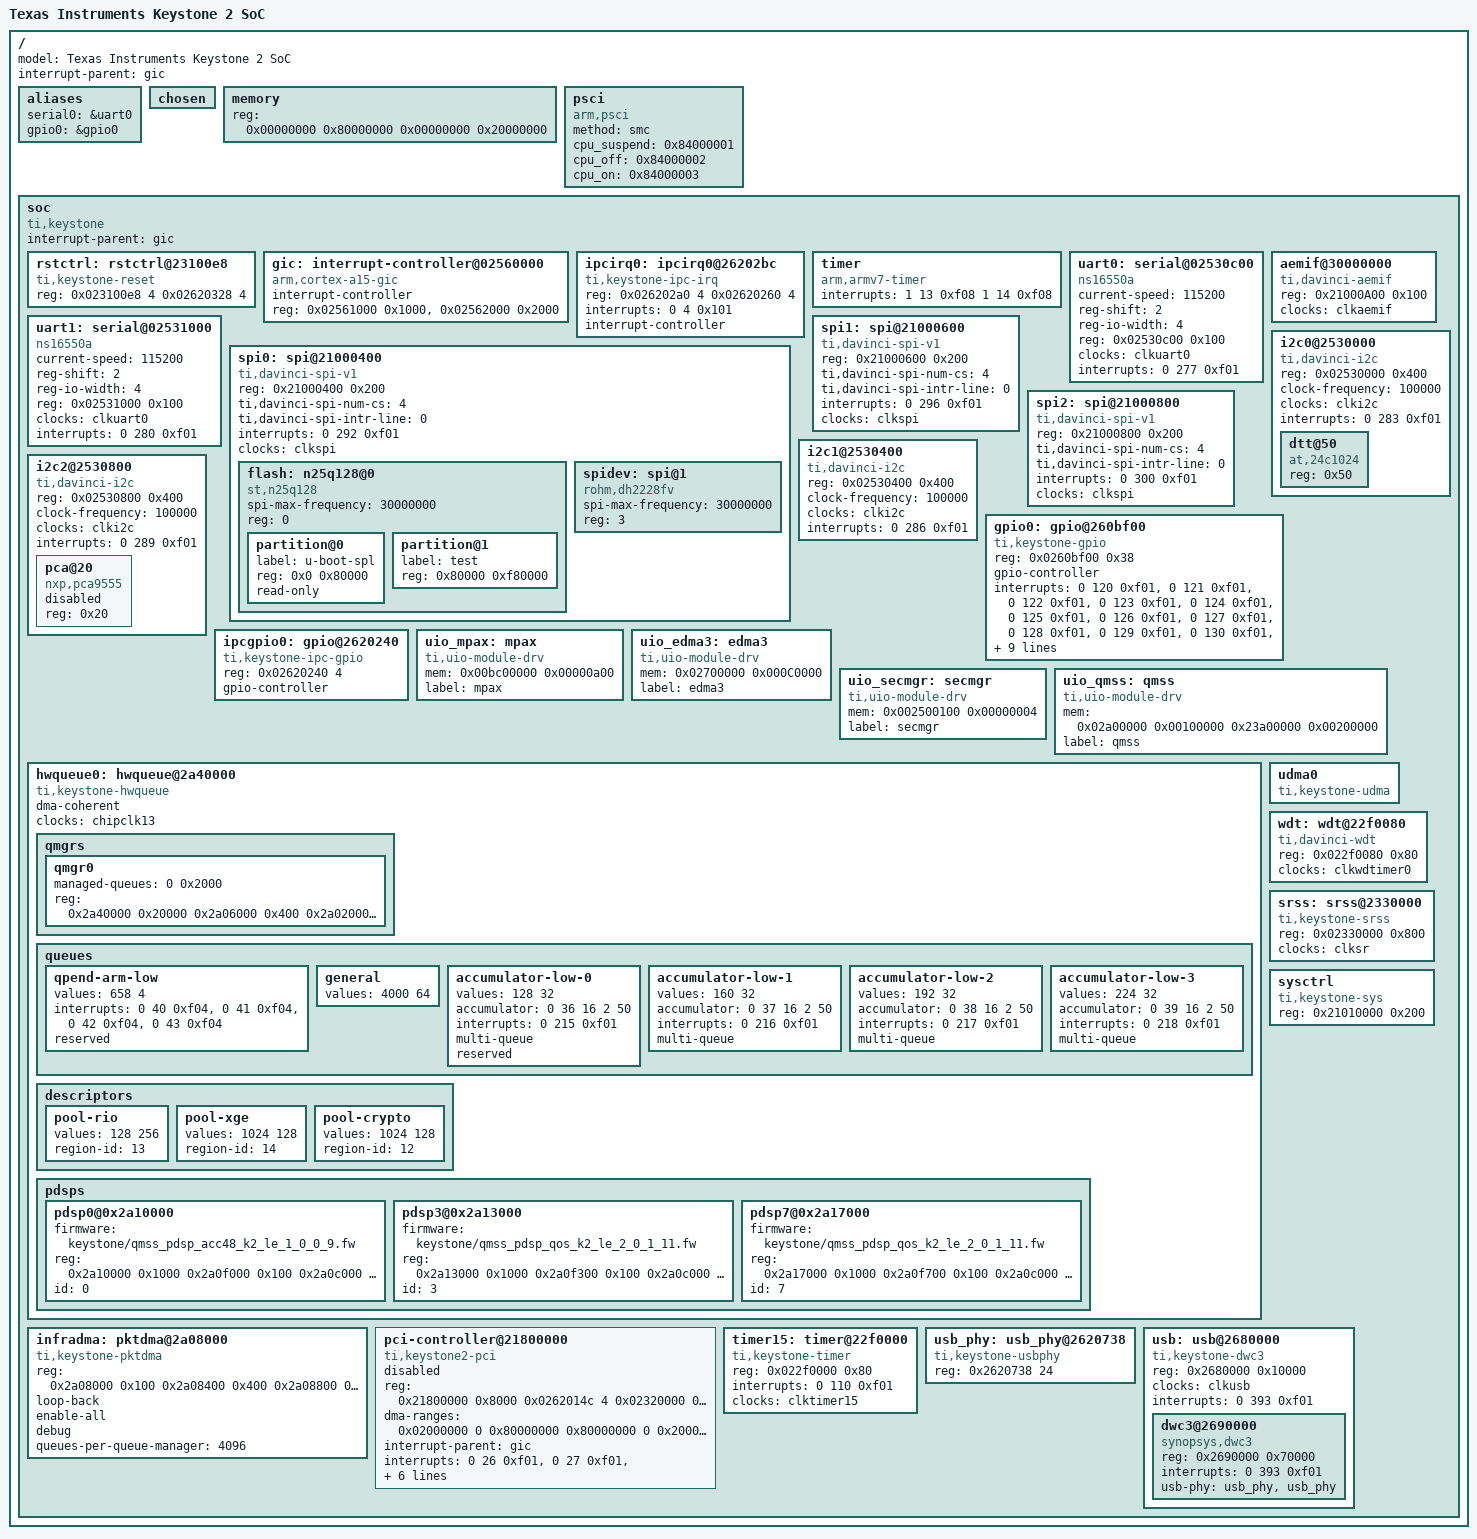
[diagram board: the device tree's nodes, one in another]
/*
 * Copyright 2014 Texas Instruments, Inc.
 *
 * Common DT bindings for Keystone SoCs
 *
 * This program is free software; you can redistribute it and/or modify
 * it under the terms of the GNU General Public License version 2 as
 * published by the Free Software Foundation.
 */

/include/ "skeleton.dtsi"

/ {
	model = "Texas Instruments Keystone 2 SoC";
	#address-cells = <2>;
	#size-cells = <2>;
	interrupt-parent = <&gic>;

	aliases {
		serial0	= &uart0;
		gpio0   = &gpio0;
	};

	chosen {
	};

	memory {
		reg = <0x00000000 0x80000000 0x00000000 0x20000000>;
	};

	psci {
		compatible	= "arm,psci";
		method		= "smc";
		cpu_suspend	= <0x84000001>;
		cpu_off		= <0x84000002>;
		cpu_on		= <0x84000003>;
	};

	soc {
		#address-cells = <1>;
		#size-cells = <1>;
		compatible = "ti,keystone","simple-bus";
		interrupt-parent = <&gic>;
		ranges = <0x0 0x0 0x0 0xc0000000>;

		rstctrl:rstctrl@23100e8 {
			compatible = "ti,keystone-reset";
			reg = <0x023100e8 4	/* pll reset control reg */
				0x02620328 4>;	/* rstmux8 register */
		};

		/include/ "keystone-clocks.dtsi"

		gic: interrupt-controller@02560000 {
			compatible = "arm,cortex-a15-gic";
			#interrupt-cells = <3>;
			#size-cells = <0>;
			#address-cells = <1>;
			interrupt-controller;
			reg = <0x02561000 0x1000>,
			      <0x02562000 0x2000>;
		};

		ipcirq0: ipcirq0@26202bc {	/* ipc irq chip */
			compatible = "ti,keystone-ipc-irq";
			reg  = <0x026202a0 4	/* host ack register */
			        0x02620260 4>;	/* ipc host interrupt generation
						   register */
			interrupts = <0 4 0x101>;
				/* it should match the value in irqs.h */
				/* following is the source id to irq mapping
				   SRCS0 <-> ipc hw irq 0 ... SRCS27 <-> ipc hw
				    irq 27 note that SRCS0 is bit 4 in ipc
				    register */
			interrupt-controller;
			#interrupt-cells = <2>;
		};

		timer {
			compatible = "arm,armv7-timer";
			interrupts = <1 13 0xf08 1 14 0xf08>;
		};

		uart0:	serial@02530c00 {
			compatible	= "ns16550a";
			current-speed	= <115200>;
			reg-shift	= <2>;
			reg-io-width	= <4>;
			reg		= <0x02530c00 0x100>;
			clocks		= <&clkuart0>;
			interrupts	= <0 277 0xf01>;
		};

		uart1:	serial@02531000 {
			compatible	= "ns16550a";
			current-speed	= <115200>;
			reg-shift	= <2>;
			reg-io-width	= <4>;
			reg		= <0x02531000 0x100>;
			clocks		= <&clkuart0>;
			interrupts	= <0 280 0xf01>;
		};

		aemif@30000000 {
			compatible = "ti,davinci-aemif";
			#address-cells = <2>;
			#size-cells = <1>;
			reg = <0x21000A00 0x100>;
			ranges = <2 0 0x30000000 0x08000000
				3 0 0x34000000 0x04000000
				4 0 0x38000000 0x04000000
				5 0 0x3C000000 0x04000000
				6 0 0x21000A00 0x100>;
			clocks = <&clkaemif>;
			clock-names = "aemif";
		};

		spi0:spi@21000400 {
			#address-cells			= <1>;
			#size-cells			= <0>;
			compatible			= "ti,davinci-spi-v1";
			reg				= <0x21000400 0x200>;
			ti,davinci-spi-num-cs		= <4>;
			ti,davinci-spi-intr-line	= <0>;
			interrupts			= <0 292 0xf01>;
			clocks				= <&clkspi>;

			flash: n25q128@0 {
				#address-cells = <1>;
				#size-cells = <1>;
				compatible = "st,n25q128","st,m25p";
				spi-max-frequency = <30000000>;
				reg = <0>;

				partition@0 {
					label = "u-boot-spl";
					reg = <0x0 0x80000>;
					read-only;
				};

				partition@1 {
					label = "test";
					reg = <0x80000 0xf80000>;
				};
			};

			spidev:spi@1 {
				#address-cells = <1>;
				#size-cells = <1>;
				compatible = "rohm,dh2228fv";
				spi-max-frequency = <30000000>;
				reg = <3>;
			};
		};

		spi1:spi@21000600 {
			#address-cells			= <1>;
			#size-cells			= <0>;
			compatible			= "ti,davinci-spi-v1";
			reg				= <0x21000600 0x200>;
			ti,davinci-spi-num-cs		= <4>;
			ti,davinci-spi-intr-line	= <0>;
			interrupts			= <0 296 0xf01>;
			clocks				= <&clkspi>;
		};

		spi2:spi@21000800 {
			#address-cells			= <1>;
			#size-cells			= <0>;
			compatible			= "ti,davinci-spi-v1";
			reg				= <0x21000800 0x200>;
			ti,davinci-spi-num-cs		= <4>;
			ti,davinci-spi-intr-line	= <0>;
			interrupts			= <0 300 0xf01>;
			clocks				= <&clkspi>;
		};

		i2c0@2530000 {
			compatible = "ti,davinci-i2c";
			reg = <0x02530000 0x400>;
			clock-frequency = <100000>;
			clocks		= <&clki2c>;
			interrupts	= <0 283 0xf01>;
			#address-cells = <1>;
			#size-cells = <0>;

			dtt@50 {
				compatible = "at,24c1024";
				reg = <0x50>;
			};
		};

		i2c1@2530400 {
			compatible = "ti,davinci-i2c";
			reg = <0x02530400 0x400>;
			clock-frequency = <100000>;
			clocks		= <&clki2c>;
			interrupts	= <0 286 0xf01>;
			#address-cells = <1>;
			#size-cells = <0>;

		};

		i2c2@2530800 {
			compatible = "ti,davinci-i2c";
			reg = <0x02530800 0x400>;
			clock-frequency = <100000>;
			clocks		= <&clki2c>;
			interrupts	= <0 289 0xf01>;
			#address-cells = <1>;
			#size-cells = <0>;

			pca@20 {
				compatible = "nxp,pca9555";
				status = "disabled";
				reg = <0x20>;
			};
		};

		gpio0: gpio@260bf00 {
			compatible = "ti,keystone-gpio";
			reg = <0x0260bf00 0x38>;
			gpio-controller;
			#gpio-cells = <2>;
			/* HW Interrupts mapped to GPIO pins */
			interrupts = <0 120 0xf01>,
				<0 121 0xf01>,
				<0 122 0xf01>,
				<0 123 0xf01>,
				<0 124 0xf01>,
				<0 125 0xf01>,
				<0 126 0xf01>,
				<0 127 0xf01>,
				<0 128 0xf01>,
				<0 129 0xf01>,
				<0 130 0xf01>,
				<0 131 0xf01>,
				<0 132 0xf01>,
				<0 133 0xf01>,
				<0 134 0xf01>,
				<0 135 0xf01>,
				<0 136 0xf01>,
				<0 137 0xf01>,
				<0 138 0xf01>,
				<0 139 0xf01>,
				<0 140 0xf01>,
				<0 141 0xf01>,
				<0 142 0xf01>,
				<0 143 0xf01>,
				<0 144 0xf01>,
				<0 145 0xf01>,
				<0 146 0xf01>,
				<0 147 0xf01>,
				<0 148 0xf01>,
				<0 149 0xf01>,
				<0 150 0xf01>,
				<0 151 0xf01>;
			interrupt-controller;
			#interrupt-cells = <2>;
			clocks = <&clkgpio>;
			clock-names = "gpio";
		};

		ipcgpio0: gpio@2620240 {
			compatible = "ti,keystone-ipc-gpio";
			reg = <0x02620240 4>;
			gpio-controller;
			#gpio-cells = <2>;
		};

		uio_mpax: mpax {
			compatible = "ti,uio-module-drv";
			mem  = <0x00bc00000 0x00000a00>;
			label = "mpax";
		};

		uio_edma3: edma3 {
			compatible = "ti,uio-module-drv";
			mem = <0x02700000 0x000C0000>;
			label = "edma3";
		};
		uio_secmgr: secmgr {
			compatible = "ti,uio-module-drv";
			mem  = <0x002500100 0x00000004>;
			label = "secmgr";
		};
		uio_qmss: qmss {
			compatible = "ti,uio-module-drv";
			mem  = <0x02a00000 0x00100000
				0x23a00000 0x00200000>;
			label = "qmss";
		};

		hwqueue0: hwqueue@2a40000 {
			compatible = "ti,keystone-hwqueue";
			dma-coherent;
			#address-cells = <1>;
			#size-cells = <1>;
			clocks = <&chipclk13>;
			clock-names = "clk_hwqueue";
			ranges;

			qmgrs {
				#address-cells = <1>;
				#size-cells = <1>;
				ranges;
				qmgr0 {
					managed-queues = <0 0x2000>;
					reg = <0x2a40000 0x20000 /* 0 - peek */
					       0x2a06000 0x400 /* 1 - status */
					       0x2a02000 0x1000	/* 2 - config */
					       0x2a03000 0x1000	/* 3 - region */
					       0x2a80000 0x20000 /* 4 - push */
					       0x2a80000 0x20000>; /* 5 - pop */
				};
			};
			queues {
				qpend-arm-low {
					values = <658 4>;
					interrupts = <0 40 0xf04>,
						<0 41 0xf04>,
						<0 42 0xf04>,
						<0 43 0xf04>;
					reserved;
				};
				general {
					values = <4000 64>;
				};
				accumulator-low-0 {
					values = <128 32>;
					/* pdsp-id, channel, entries,
					    pacing mode, latency */
					accumulator = <0 36 16 2 50>;
					interrupts = <0 215 0xf01>;
					multi-queue;
					reserved;
				};
				accumulator-low-1 {
					values = <160 32>;
					/* pdsp-id, channel, entries,
					    pacing mode, latency */
					accumulator = <0 37 16 2 50>;
					interrupts = <0 216 0xf01>;
					multi-queue;
				};
				accumulator-low-2 {
					values = <192 32>;
					/* pdsp-id, channel, entries,
					    pacing mode, latency */
					accumulator = <0 38 16 2 50>;
					interrupts = <0 217 0xf01>;
					multi-queue;
				};
				accumulator-low-3 {
					values = <224 32>;
					/* pdsp-id, channel, entries,
					    pacing mode, latency */
					accumulator = <0 39 16 2 50>;
					interrupts = <0 218 0xf01>;
					multi-queue;
				};
			};
			descriptors {
				pool-rio {
					values = <128 256>;
					region-id = <13>;
				};
				pool-xge {
					values = <1024 128>;
					region-id = <14>;
				};
				pool-crypto {
					values = <1024 128>;	/* num_desc desc_size */
					region-id = <12>;
				};
			};
			pdsps {
				#address-cells = <1>;
				#size-cells = <1>;
				ranges;
				pdsp0@0x2a10000 {
					firmware = "keystone/qmss_pdsp_acc48_k2_le_1_0_0_9.fw";
					reg = <0x2a10000 0x1000    /*iram */
					       0x2a0f000 0x100     /*reg*/
					       0x2a0c000 0x3c8	   /*intd */
					       0x2a20000 0x4000>;  /*cmd*/
					id = <0>;
				};
				pdsp3@0x2a13000 {
					firmware = "keystone/qmss_pdsp_qos_k2_le_2_0_1_11.fw";
					reg = <0x2a13000 0x1000    /*iram */
					       0x2a0f300 0x100     /*reg*/
					       0x2a0c000 0x3c8	   /*intd */
					       0x2a2c000 0x4000>;  /*cmd*/
					id = <3>;
				};
				pdsp7@0x2a17000 {
					firmware = "keystone/qmss_pdsp_qos_k2_le_2_0_1_11.fw";
					reg = <0x2a17000 0x1000    /*iram */
					       0x2a0f700 0x100     /*reg*/
					       0x2a0c000 0x3c8	   /*intd */
					       0x2a3c000 0x4000>;  /*cmd*/
					id = <7>;
				};
			};
		}; /* hwqueue0 */

		udma0 {
			compatible = "ti,keystone-udma";
		};

		infradma: pktdma@2a08000 {
			compatible = "ti,keystone-pktdma";
			reg = <0x2a08000 0x100		/* 0 - global  */
			       0x2a08400 0x400		/* 1 - txchan  */
			       0x2a08800 0x400		/* 2 - rxchan  */
			       0x2a08c00 0x080		/* 3 - txsched */
			       0x2a09000 0x400>;	/* 4 - rxflow  */
			loop-back;
			/* big-endian; */
			enable-all;
			debug;
			/* rx-priority = <0>; */
			/* tx-priority = <0>; */
			queues-per-queue-manager = <4096>;
		};

		pci-controller@21800000 {
			device_type = "pci";
			#address-cells = <3>;
			#size-cells = <2>;
			#interrupt-cells = <2>;
			status = "disabled";
			compatible = "ti,keystone2-pci";
			reg =  <0x21800000 0x8000   /* pcie-regs */
				0x0262014c 4	    /* device cfg */
				0x02320000 0x4000>; /* Keystone2 serdes cfg */

			/* outbound pci resources */
			ranges = <0x02000000 0 0x50000000 0x50000000 0
				 0x10000000 0x01000000 0 0 0x23250000 0 0x4000>;

			/* inbound dma range */
			dma-ranges = <0x02000000 0 0x80000000 0x80000000 0
				      0x20000000>;

			interrupt-parent = <&gic>;
			interrupts = <0 26 0xf01>,
				<0 27 0xf01>,
				<0 28 0xf01>,
				<0 29 0xf01>, /* 4 Legacy IRQs */
				<0 30 0xf01>,
				<0 31 0xf01>,
				<0 32 0xf01>,
				<0 33 0xf01>, /* 8 MSI IRQs */
				<0 34 0xf01>,
				<0 35 0xf01>,
				<0 36 0xf01>,
				<0 37 0xf01>,
				<0 38 0xf01>; /* Error IRQ */
			clocks = <&clkpcie>;
			clock-names = "pcie";
			enable-linktrain; /* When the boot loader enables link
					     train and configure ep remove this
					     attribute */
		};

		wdt: wdt@22f0080 {
			compatible = "ti,davinci-wdt";
			reg = <0x022f0080 0x80>;
			clocks = <&clkwdtimer0>;
			clock-names = "watchdog";
		};

		timer15: timer@22f0000 {
			compatible = "ti,keystone-timer";
			reg = <0x022f0000 0x80>;
			interrupts = <0 110 0xf01>;
			clocks = <&clktimer15>;
		};

                srss: srss@2330000 {
                        compatible = "ti,keystone-srss";
                        reg = <0x02330000 0x800>;
                        clocks = <&clksr>;
                        clock-names = "srssclock";
                };

		sysctrl {
			/*
			 * add all system level resources here that are used by
			 * keystone soc code. Move rstctrl contents to this node
			 */
			compatible = "ti,keystone-sys";
			reg = <0x21010000 0x200>; /* DDR3 controller reg */
		};

		usb_phy: usb_phy@2620738 {
			compatible = "ti,keystone-usbphy";
			#address-cells = <1>;
			#size-cells = <1>;
			reg = <0x2620738 24>;
		};

		usb: usb@2680000 {
			compatible = "ti,keystone-dwc3";
			#address-cells = <1>;
			#size-cells = <1>;
			reg = <0x2680000 0x10000>;
			clocks = <&clkusb>;
			clock-names = "usb";
			interrupts = <0 393 0xf01>;
			ranges;

			dwc3@2690000 {
				compatible = "synopsys,dwc3";
				reg = <0x2690000 0x70000>;
				interrupts = <0 393 0xf01>;
				usb-phy = <&usb_phy>, <&usb_phy>;
			};
		};

	};
};
